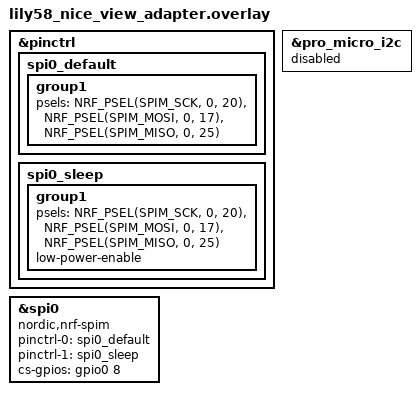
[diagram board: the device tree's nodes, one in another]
/*
 * nice!view wiring for the PandaKB Lily58 on nice_nano_v2 / SuperMini.
 * Same as ZMK's nice_view_adapter, except CS is P0.08 (D0) instead of
 * P0.06 (D1), because P0.06 is the WS2812 data line on this PCB.
 * Pin choice copied from PandaKB's Corne nice_view_adapter. Unverified
 * on the Lily58 PCB; if the screen stays garbage, try P0.22 (D4).
 */

&pinctrl {
    spi0_default: spi0_default {
        group1 {
            psels = <NRF_PSEL(SPIM_SCK, 0, 20)>,
                <NRF_PSEL(SPIM_MOSI, 0, 17)>,
                <NRF_PSEL(SPIM_MISO, 0, 25)>;
        };
    };
    spi0_sleep: spi0_sleep {
        group1 {
            psels = <NRF_PSEL(SPIM_SCK, 0, 20)>,
                <NRF_PSEL(SPIM_MOSI, 0, 17)>,
                <NRF_PSEL(SPIM_MISO, 0, 25)>;
            low-power-enable;
        };
    };
};

nice_view_spi: &spi0 {
    compatible = "nordic,nrf-spim";
    pinctrl-0 = <&spi0_default>;
    pinctrl-1 = <&spi0_sleep>;
    pinctrl-names = "default", "sleep";
    cs-gpios = <&gpio0 8 GPIO_ACTIVE_HIGH>;
};

&pro_micro_i2c {
    status = "disabled";
};
